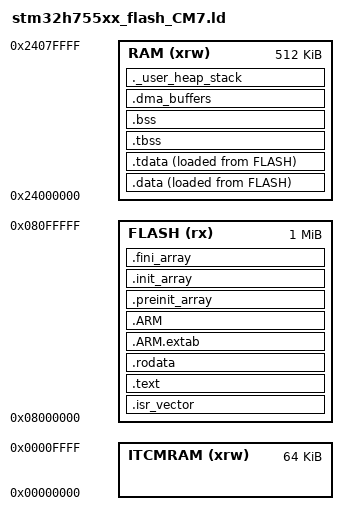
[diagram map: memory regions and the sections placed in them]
/*
******************************************************************************
**
**  File        : LinkerScript.ld
**
**
**  Abstract    : Linker script for STM32H7 series
**                1024Kbytes FLASH and 192Kbytes RAM
**
**                Set heap size, stack size and stack location according
**                to application requirements.
**
**                Set memory bank area and size if external memory is used.
**
**  Target      : STMicroelectronics STM32
**
**  Distribution: The file is distributed as is without any warranty
**                of any kind.
**
*****************************************************************************
** @attention
**
** Copyright (c) 2019 STMicroelectronics.
** All rights reserved.
**
** This software is licensed under terms that can be found in the LICENSE file
** in the root directory of this software component.
** If no LICENSE file comes with this software, it is provided AS-IS.
**
******************************************************************************
*/

/* Entry Point */
ENTRY(Reset_Handler)


/* Specify the memory areas */
MEMORY
{
FLASH (rx)      : ORIGIN = 0x08000000, LENGTH = 1024K
RAM (xrw)      : ORIGIN = 0x24000000, LENGTH = 512K
ITCMRAM (xrw)      : ORIGIN = 0x00000000, LENGTH = 64K
}
/*
 * RAM here is AXI SRAM (D1 domain, 0x24000000, 512K per ST's own
 * datasheet - confirmed, not guessed), not DTCM (0x20000000, 128K) as
 * ST's bare CMSIS template defaults to. Two reasons to move it, found
 * when this project's real buffer sizes (dsp_scratch, ADC/DAC rings,
 * codec2's static allocations) overflowed DTCM's 128K:
 *   1. Size: 512K vs 128K.
 *   2. DTCM is only reachable by the CPU core itself (and MDMA) on H7 -
 *      NOT by the general-purpose DMA1/DMA2 controllers this project's
 *      ADC/DAC transfers use. Buffers placed there would have looked
 *      fine at link time and then silently failed on real hardware (DMA
 *      never actually reaching them) - worse than the build-time error
 *      that actually caught this.
 * DTCM (0x20000000, 128K) is still physically there and usable (e.g. for
 * a future stack/heap split favoring its zero-wait-state access), just
 * not managed by this linker script yet.
 */
/* Highest address of the user mode stack */
_estack = 0x24080000;    /* end of RAM (AXI SRAM, 0x24000000 + 512K) */
/* Generate a link error if heap and stack don't fit into RAM */
_Min_Heap_Size = 0x8000;      /* required amount of heap - CubeMX default (0x200) was too
                                  tight for FreeDV/codec2's runtime allocations (LPC/LDPC
                                  codebooks etc); ~205K of 512K RAM is in use by data+bss,
                                  plenty of headroom for this. */
_Min_Stack_Size = 0x4000; /* required amount of stack */

/* Define output sections */
SECTIONS
{
  /* The startup code goes first into FLASH */
  .isr_vector :
  {
    . = ALIGN(4);
    KEEP(*(.isr_vector)) /* Startup code */
    . = ALIGN(4);
  } >FLASH

  /* The program code and other data goes into FLASH */
  .text :
  {
    . = ALIGN(4);
    *(.text)           /* .text sections (code) */
    *(.text*)          /* .text* sections (code) */
    *(.glue_7)         /* glue arm to thumb code */
    *(.glue_7t)        /* glue thumb to arm code */
    *(.eh_frame)

    KEEP (*(.init))
    KEEP (*(.fini))

    . = ALIGN(4);
    _etext = .;        /* define a global symbols at end of code */
  } >FLASH

  /* Constant data goes into FLASH */
  .rodata :
  {
    . = ALIGN(4);
    *(.rodata)         /* .rodata sections (constants, strings, etc.) */
    *(.rodata*)        /* .rodata* sections (constants, strings, etc.) */
    . = ALIGN(4);
  } >FLASH

  .ARM.extab (READONLY) : /* The READONLY keyword is only supported in GCC11 and later, remove it if using GCC10 or earlier. */
  {
    . = ALIGN(4);
    *(.ARM.extab* .gnu.linkonce.armextab.*)
    . = ALIGN(4);
  } >FLASH
  .ARM (READONLY) : /* The READONLY keyword is only supported in GCC11 and later, remove it if using GCC10 or earlier. */
  {
    . = ALIGN(4);
    __exidx_start = .;
    *(.ARM.exidx*)
    __exidx_end = .;
    . = ALIGN(4);
  } >FLASH

  .preinit_array (READONLY) : /* The READONLY keyword is only supported in GCC11 and later, remove it if using GCC10 or earlier. */
  {
    . = ALIGN(4);
    PROVIDE_HIDDEN (__preinit_array_start = .);
    KEEP (*(.preinit_array*))
    PROVIDE_HIDDEN (__preinit_array_end = .);
    . = ALIGN(4);
  } >FLASH
  .init_array (READONLY) : /* The READONLY keyword is only supported in GCC11 and later, remove it if using GCC10 or earlier. */
  {
    . = ALIGN(4);
    PROVIDE_HIDDEN (__init_array_start = .);
    KEEP (*(SORT(.init_array.*)))
    KEEP (*(.init_array*))
    PROVIDE_HIDDEN (__init_array_end = .);
    . = ALIGN(4);
  } >FLASH
  .fini_array (READONLY) : /* The READONLY keyword is only supported in GCC11 and later, remove it if using GCC10 or earlier. */
  {
    . = ALIGN(4);
    PROVIDE_HIDDEN (__fini_array_start = .);
    KEEP (*(SORT(.fini_array.*)))
    KEEP (*(.fini_array*))
    PROVIDE_HIDDEN (__fini_array_end = .);
    . = ALIGN(4);
  } >FLASH

  /* used by the startup to initialize data */
  _sidata = LOADADDR(.data);

  /* Initialized data sections goes into RAM, load LMA copy after code */
  .data : 
  {
    . = ALIGN(4);
    _sdata = .;        /* create a global symbol at data start */
    *(.data)           /* .data sections */
    *(.data*)          /* .data* sections */

    . = ALIGN(4);
  } >RAM AT> FLASH

  /* Initialized TLS data section */
  .tdata : ALIGN(4)
  {
    *(.tdata .tdata.* .gnu.linkonce.td.*)
    . = ALIGN(4);
    _edata = .;        /* define a global symbol at data end */
    PROVIDE(__data_end = .);
    PROVIDE(__tdata_end = .);
  } >RAM AT> FLASH

  PROVIDE( __tdata_start = ADDR(.tdata) );
  PROVIDE( __tdata_size = __tdata_end - __tdata_start );

  PROVIDE( __data_start = ADDR(.data) );
  PROVIDE( __data_size = __data_end - __data_start );

  PROVIDE( __tdata_source = LOADADDR(.tdata) );
  PROVIDE( __tdata_source_end = LOADADDR(.tdata) + SIZEOF(.tdata) );
  PROVIDE( __tdata_source_size = __tdata_source_end - __tdata_source );

  PROVIDE( __data_source = LOADADDR(.data) );
  PROVIDE( __data_source_end = __tdata_source_end );
  PROVIDE( __data_source_size = __data_source_end - __data_source );


  
  /* Uninitialized data section */
  /* Uninitialized TLS data section */
  .tbss (NOLOAD) : ALIGN(4)
  {
    _sbss = .;         /* define a global symbol at bss start */
    __bss_start__ = _sbss;
    *(.tbss .tbss.*)
    . = ALIGN(4);
    PROVIDE( __tbss_end = . );
  } >RAM

  PROVIDE( __tbss_start = ADDR(.tbss) );
  PROVIDE( __tbss_size = __tbss_end - __tbss_start );
  PROVIDE( __tbss_offset = ADDR(.tbss) - ADDR(.tdata) );

  PROVIDE( __tls_base = __tdata_start );
  PROVIDE( __tls_end = __tbss_end );
  PROVIDE( __tls_size = __tls_end - __tls_base );
  PROVIDE( __tls_align = MAX(ALIGNOF(.tdata), ALIGNOF(.tbss)) );
  PROVIDE( __tls_size_align = (__tls_size + __tls_align - 1) & ~(__tls_align - 1) );
  PROVIDE( __arm32_tls_tcb_offset = MAX(8, __tls_align) );
  PROVIDE( __arm64_tls_tcb_offset = MAX(16, __tls_align) );

  .bss (NOLOAD) : ALIGN(4)
  {
    /* This is used by the startup in order to initialize the .bss section */
    *(.bss)
    *(.bss*)
    *(COMMON)

    . = ALIGN(4);
    _ebss = .;         /* define a global symbol at bss end */
    __bss_end__ = _ebss;
      PROVIDE( __bss_end = .);
  } >RAM
  PROVIDE( __non_tls_bss_start = ADDR(.bss) );

  PROVIDE( __bss_start = __tbss_start );
  PROVIDE( __bss_size = __bss_end - __bss_start );

  /* ADC/DAC ring buffers (adc_buffer/dac_buffer/sidetone_buffer, main.c) -
     the DMA1/DMA2 controllers write/read these directly and aren't
     cache-coherent with the CPU, so they're pulled out of the now-enabled
     D-Cache via an MPU region covering exactly this section (see
     MPU_InitStruct in main.c). 32KB, 32KB-aligned: ARMv7-M MPU regions
     need a power-of-two size with a naturally-aligned base address. */
  .dma_buffers (NOLOAD) : ALIGN(0x8000)
  {
    __dma_buffers_start = .;
    *(.dma_buffers)
    . = ALIGN(0x8000);
    __dma_buffers_end = .;
  } >RAM

  /* User_heap_stack section, used to check that there is enough RAM left */
  ._user_heap_stack (NOLOAD) :
  {
    . = ALIGN(8);
    PROVIDE ( end = . );
    PROVIDE ( _end = . );
    . = . + _Min_Heap_Size;
    . = . + _Min_Stack_Size;
    . = ALIGN(8);
  } >RAM

  

  /* Remove information from the standard libraries */
  /DISCARD/ :
  {
    libc.a:* ( * )
    libm.a:* ( * )
    libgcc.a:* ( * )
  }

  .ARM.attributes 0 : { *(.ARM.attributes) }
}


